# gcr_me12 register map
Registers are access not given, no defined reset value unless marked. A register's access mark holds for its fields unless they carry their own. Offsets are from the block's base; lines under a group give offsets from that group; [hi:lo] are bit positions; {n}, {i} and the like mark numbered series; 'fields as' and 'values as' point back to an identical list; <NAME> marks a mode.

## Memory map
0x40000000 GCR size 0x400 — Global Control Registers.

## GCR — Global Control Registers.
Base 0x40000000
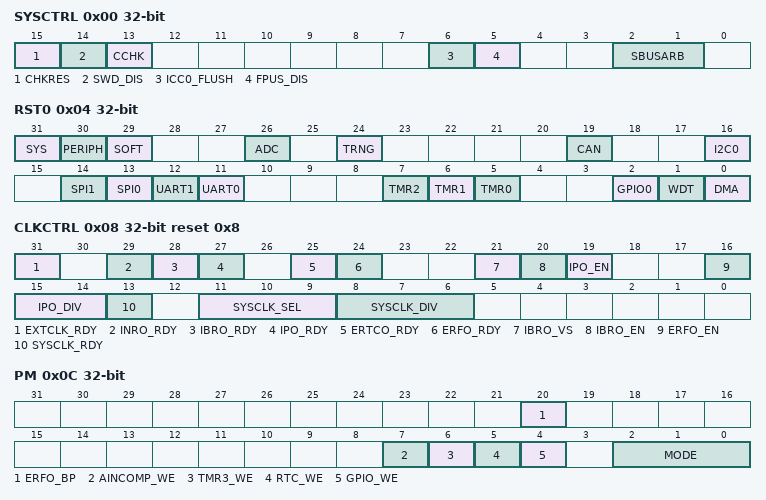
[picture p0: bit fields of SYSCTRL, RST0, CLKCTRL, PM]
0x00 SYSCTRL — System Control.
  [15] CHKRES — ROM Checksum Result. This bit is valid when the checksum is done and the CCHK bit is cleared.
    0=pass (ROM Checksum Correct.); 1=fail (ROM Checksum Fail.)
  [14] SWD_DIS — Serial Wire Debug Disable.
  [13] CCHK — Compute ROM Checksum. This bit is self-cleared when calculation is completed. Once set, software clearing this bit is ignored and the bit will remain set until the operation is completed.
    0=complete (No operation/complete.); 1=Start operation
  [6] ICC0_FLUSH — Code Cache Flush. This bit is used to flush the code caches and the instruction buffer of the Cortex-M4.
    0=Normal Code Cache Operation; 1=flush (Code Caches and CPU instruction buffer are flushed)
  [5] FPUS_DIS — Cortex M4 Floating Point Disable This bit is used to disable the floating-point unit of the Cortex-M4.
  [2:1] SBUSARB — System bus arbitration scheme. These bits are used to select between Fixed burst arbitration and Round Robin scheme. The Round Robin scheme is selected by default.
0x04 RST0 — Reset.
  [all] fields
    0=reset_done (Reset complete.); 1=busy (Starts Reset or indicates reset in progress.)
  [31] SYS — System Reset. Setting this bit to 1 resets the CPU core and all peripherals, including the watchdog timer.
  [30] PERIPH — Peripheral Reset. Setting this bit to 1 resets all peripherals. The CPU core, the watchdog timer, and all GPIO pins are unaffected by this reset.
  [29] SOFT — Soft Reset. Setting this bit to 1 resets everything except the CPU and the watchdog timer.
  [26] ADC — ADC Reset.
  [24] TRNG — TRNG Reset. This reset is only available during the manufacture testing phase.
  [19] CAN — CAN Reset.
  [16] I2C0 — I2C 0 Reset.
  [14] SPI1 — SPI 1 Reset. Setting this bit to 1 resets all SPI 1 blocks.
  [13] SPI0 — SPI 0 Reset. Setting this bit to 1 resets all SPI 0 blocks.
  [12] UART1 — UART 1 Reset. Setting this bit to 1 resets all UART 1 blocks.
  [11] UART0 — UART 0 Reset. Setting this bit to 1 resets all UART 0 blocks.
  [7] TMR2 — Timer 2 Reset. Setting this bit to 1 resets Timer 2 blocks.
  [6] TMR1 — Timer 1 Reset. Setting this bit to 1 resets Timer 1 blocks.
  [5] TMR0 — Timer 0 Reset. Setting this bit to 1 resets Timer 0 blocks.
  [2] GPIO0 — GPIO0 Reset. Setting this bit to 1 resets GPIO0 pins to their default states.
  [1] WDT — Watchdog Timer 0 Reset.
  [0] DMA — DMA Reset.
0x08 CLKCTRL reset 0x8 — Clock Control.
  [31] EXTCLK_RDY ro — External Clock GPIO0_28 AF2 Ready. Clock is ready when AF2 is enabled for GPIO0_28
    0=not (Is not Ready.); 1=ready (Is Ready.)
  [29] INRO_RDY ro — 8 kHz Low Frequency Reference Clock Ready.
    0=not (Is not Ready.); 1=ready (Is Ready.)
  [28] IBRO_RDY ro — 7.3725 MHz HIRC Ready.
    0=not (Is not Ready.); 1=ready (Is Ready.)
  [27] IPO_RDY ro — 100 MHz Clock Ready.
    0=not (Is not Ready.); 1=ready (Is Ready.)
  [25] ERTCO_RDY ro — 32 kHz Crystal Oscillator Ready
    0=not (Is not Ready.); 1=ready (Is Ready.)
  [24] ERFO_RDY ro — 32 MHz Oscillator Ready
    0=not (Is not Ready.); 1=ready (Is Ready.)
  [21] IBRO_VS — 7.3725 MHz High Frequency Internal Reference Clock Voltage Select. This register bit is used to select the power supply to the IBRO.
    0=VCore Supply; 1=1V (Dedicated 1V regulated supply.)
  [20] IBRO_EN — 7.3725 MHz Clock Enable.
    0=dis (Is Disabled.); 1=en (Is Enabled.)
  [19] IPO_EN — 100 MHz Clock Enable.
    0=dis (Is Disabled.); 1=en (Is Enabled.)
  [16] ERFO_EN — 32 MHz Crystal Oscillator Enable.
    0=dis (Is Disabled.); 1=en (Is Enabled.)
  [15:14] IPO_DIV — HIRC96M Source Clock Divider.
    0=DIV1; 1=DIV2; 2=DIV4; 3=DIV8
  [13] SYSCLK_RDY ro — Clock Ready. This read only bit reflects whether the currently selected system clock source is running.
    0=busy (Switchover to the new clock source (as selected by CLKSEL) has not yet occurred.); 1=ready (System clock running from CLKSEL clock source.)
  [11:9] SYSCLK_SEL — Clock Source Select. This 3 bit field selects the source for the system clock.
    2=ERFO (The external 32 MHz input is used for the system clock.); 3=INRO (8 kHz LIRC is used for the system clock.); 4=IPO (The internal 100 MHz oscillator is used for the system clock.); 5=IBRO (The internal 7.3725 MHz oscillator is used for the system clock.); 6=ERTCO (External 32 kHz input is used for the system clock.); 7=EXTCLK (External clock input is used for the system clock.)
  [8:6] SYSCLK_DIV — Prescaler Select. This 3 bit field sets the system operating frequency by controlling the prescaler that divides the output of the PLL0.
    0=div1 (Divide by 1.); 1=div2 (Divide by 2.); 2=div4 (Divide by 4.); 3=div8 (Divide by 8.); 4=div16 (Divide by 16.); 5=div32 (Divide by 32.); 6=div64 (Divide by 64.); 7=div128 (Divide by 128.)
0x0C PM — Power Management.
  [20] ERFO_BP — ERFO Bypass
  [7] AINCOMP_WE — AINCOMP Wake Up Enable. This bit enables the AINCOMP Timer as wakeup source.
    0=dis (Wake Up Disable.); 1=en (Wake Up Enable.)
  [6] TMR3_WE — TMR3 (LPTMR0) Wake Up Enable. This bit enables TMR3 IRQ as wakeup source
    0=dis (Wake Up Disable.); 1=en (Wake Up Enable.)
  [5] RTC_WE — RTC Alarm Wake Up Enable. This bit enables RTC alarm as wakeup source. If enabled, the desired RTC alarm must be configured via the RTC control registers.
    0=dis (Wake Up Disable.); 1=en (Wake Up Enable.)
  [4] GPIO_WE — GPIO Wake Up Enable. This bit enables all GPIO pins as potential wakeup sources. Any GPIO configured for wakeup is capable of causing an exit from IDLE or STANDBY modes when this bit is set.
    0=dis (Wake Up Disable.); 1=en (Wake Up Enable.)
  [2:0] MODE — Operating Mode. This three bit field selects the current operating mode for the device. Note that code execution only occurs during ACTIVE mode.
    0=Active Mode; 4=Backup Mode; 7=Shutdown Mode
0x18 PCLKDIV reset 0x1 — Peripheral Clock Divider.
  [1:0] AON_CLKDIV — Always-ON (AON) domain Clock Divider. These bits define the AON domain clock divider.
    0=DIV4; 1=DIV8; 2=DIV16; 3=DIV32 (div8)
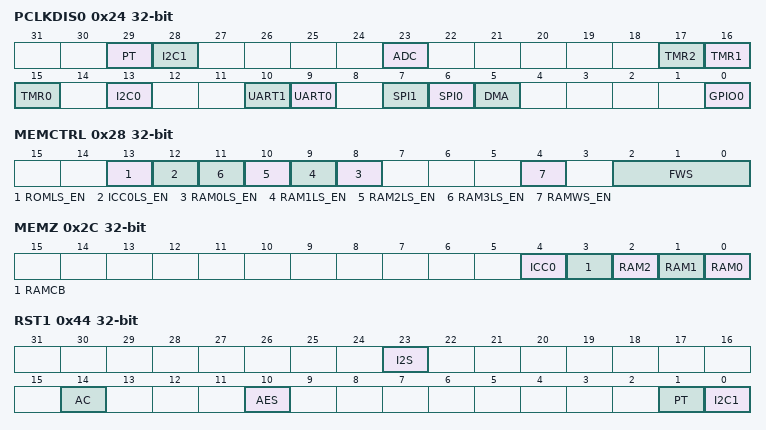
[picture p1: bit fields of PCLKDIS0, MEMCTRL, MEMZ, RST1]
0x24 PCLKDIS0 — Peripheral Clock Disable.
  [all] fields
    0=en (enable it.); 1=dis (disable it.)
  [29] PT — Pluse Train Clock Disable.
  [28] I2C1 — I2C 1 Clock Disable.
  [23] ADC — ADC Clock Disable.
  [17] TMR2 — Timer 2 Clock Disable.
  [16] TMR1 — Timer 1 Clock Disable.
  [15] TMR0 — Timer 0 Clock Disable.
  [13] I2C0 — I2C 0 Clock Disable.
  [10] UART1 — UART 1 Clock Disable.
  [9] UART0 — UART 0 Clock Disable.
  [7] SPI1 — SPI 1 Clock Disable.
  [6] SPI0 — SPI 0 Clock Disable.
  [5] DMA — DMA Clock Disable.
  [0] GPIO0 — GPIO0 Clock Disable.
0x28 MEMCTRL — Memory Clock Control Register.
  [13] ROMLS_EN — ROM Light Sleep mode.
  [12] ICC0LS_EN — Internal Cache Controller RAM Light Sleep mode.
  [n+8] RAM{n}LS_EN (n=0..3) — System RAM {n} Light Sleep mode.
  [4] RAMWS_EN — System RAM Wait State enable.
  [2:0] FWS — Flash Wait State. These bits define the number of wait-state cycles per Flash data read access. Minimum wait state is 2.
0x2C MEMZ — Memory Zeroize Control.
  [all] fields
    0=nop (No operation/complete.); 1=Start operation
  [4] ICC0 — Internal Cache Controller Data and Tag RAM Zeroization.
  [3] RAMCB — System RAM Check Bit Block Zeroization.
  [2] RAM2 — System RAM Block 2 Zeroization.
  [1] RAM1 — System RAM Block 1 Zeroization.
  [0] RAM0 — System RAM Block 0 Zeroization.
0x40 SYSST — System Status Register.
  [0] ICELOCK — ARM ICE Lock Status.
    0=unlocked (ICE is unlocked.); 1=locked (ICE is locked.)
0x44 RST1 — Reset 1.
  [all] fields
    on read: 0=reset_done (Reset complete.); 1=busy (Starts reset or indicates reset in progress.)
  [23] I2S — I2S Reset.
  [14] AC — AC Reset.
  [10] AES — AES Reset.
  [1] PT — PT Reset.
  [0] I2C1 — I2C1 Reset.
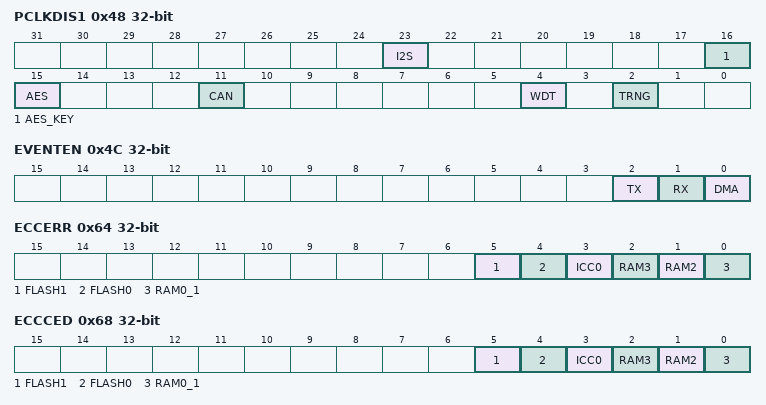
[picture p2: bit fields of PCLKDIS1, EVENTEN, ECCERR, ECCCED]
0x48 PCLKDIS1 — Peripheral Clock Disable.
  [23] I2S — I2S Clock Disable.
  [16] AES_KEY — AES Keys Clock Disable.
  [15] AES — AES Clock Disable.
  [11] CAN — CAN Clock Disable.
  [4] WDT — Watchdog Timer 0 Disable.
  [2] TRNG — TRNG Clock Disable.
0x4C EVENTEN — Event Enable Register.
  [2] TX — Enable TXEV pin event. When this bit is set, TXEV event from the CPU is output to GPIO1.9.
  [1] RX — Enable RXEV pin event. When this bit is set, RXEV event from the CPU is output to GPIO1.9.
  [0] DMA — Enable DMA event. When this bit is set, a DMA event will cause an RXEV event to wake the CPU from WFE sleep mode.
0x50 REVISION ro
  [15:0] REVISION — Manufacturer Chip Revision.
0x54 SYSIE — System Status Interrupt Enable Register.
  [0] ICEUNLOCK — ARM ICE Unlock Interrupt Enable.
    0=dis (disabled.); 1=en (enabled.)
0x64 ECCERR — ECC Error Register
  [5] FLASH1 — ECC Flash 1 Error Flag. Write 1 to clear.
  [4] FLASH0 — ECC Flash 0 Error Flag. Write 1 to clear.
  [3] ICC0 — ECC ICACHE Error Flag. Write 1 to clear.
  [2] RAM3 — ECC System RAM3 Error Flag. Write 1 to clear.
  [1] RAM2 — ECC System RAM2 Error Flag. Write 1 to clear.
  [0] RAM0_1 — ECC System RAM0 or RAM1 Error Flag. Write 1 to clear.
0x68 ECCCED — ECC Not Double Error Detect Register
  [5] FLASH1 — ECC Flash 1 Not Double Error Flag. Write 1 to clear.
  [4] FLASH0 — ECC Flash 0 Not Double Error Flag. Write 1 to clear.
  [3] ICC0 — ECC ICACHE Not Double Error Flag. Write 1 to clear.
  [2] RAM3 — ECC System RAM3 Not Double Error Flag. Write 1 to clear.
  [1] RAM2 — ECC System RAM2 Not Double Error Flag. Write 1 to clear.
  [0] RAM0_1 — ECC System RAM0 or RAM1 Not Double Error Flag. Write 1 to clear.
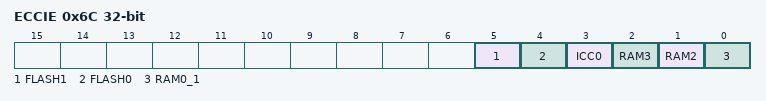
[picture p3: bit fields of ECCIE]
0x6C ECCIE — ECC IRQ Enable Register
  [5] FLASH1 — Flash 1 ECC Interrupt Enable.
  [4] FLASH0 — Flash 0 ECC Interrupt Enable.
  [3] ICC0 — ICACHE ECC Interrupt Enable.
  [2] RAM3 — System RAM3 ECC Interrupt Enable.
  [1] RAM2 — System RAM2 ECC Interrupt Enable.
  [0] RAM0_1 — System RAM0 or RAM1 ECC Interrupt Enable.
0x70 ECCADDR — ECC Error Address Register
  [31:0] ERRADDR — Error Address.
